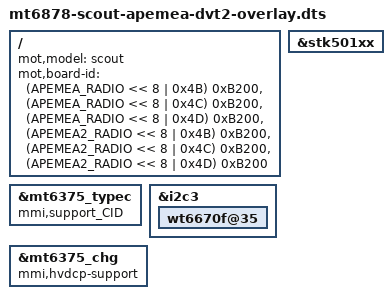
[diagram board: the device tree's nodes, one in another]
/* Copyright (c) 2023, Motorola Mobility Inc. All rights reserved.
 *
 * This program is free software; you can redistribute it and/or modify
 * it under the terms of the GNU General Public License version 2 and
 * only version 2 as published by the Free Software Foundation.
 *
 * This program is distributed in the hope that it will be useful,
 * but WITHOUT ANY WARRANTY; without even the implied warranty of
 * MERCHANTABILITY or FITNESS FOR A PARTICULAR PURPOSE.  See the
 * GNU General Public License for more details.
 */

/dts-v1/;
/plugin/;

#include "mediatek/mt6878-scout-common-overlay.dtsi"

#define APEMEA_RADIO 4
#define APEMEA2_RADIO 5

/* Board match root node */
/ {
	fragment@model {
		target-path = "/";
		__overlay__ {
			mot,model = "scout";
			mot,board-id = <(APEMEA_RADIO << 8 | 0x4B) 0xB200>, <(APEMEA_RADIO << 8 | 0x4C) 0xB200>, <(APEMEA_RADIO << 8 | 0x4D) 0xB200>, <(APEMEA2_RADIO << 8 | 0x4B) 0xB200>, <(APEMEA2_RADIO << 8 | 0x4C) 0xB200>, <(APEMEA2_RADIO << 8 | 0x4D) 0xB200>;
		};
	};
};

&mt6375_typec {
	mmi,support_CID;
};

&i2c3 {
	wt6670f@35 {
		status = "okay";
	};
};

&mt6375_chg {
	mmi,hvdcp-support;
};

&stk501xx {
	status = "okay";
};

#include <scout_evb/cust.dtsi>
/*End of this file, DO NOT ADD ANYTHING HERE*/
